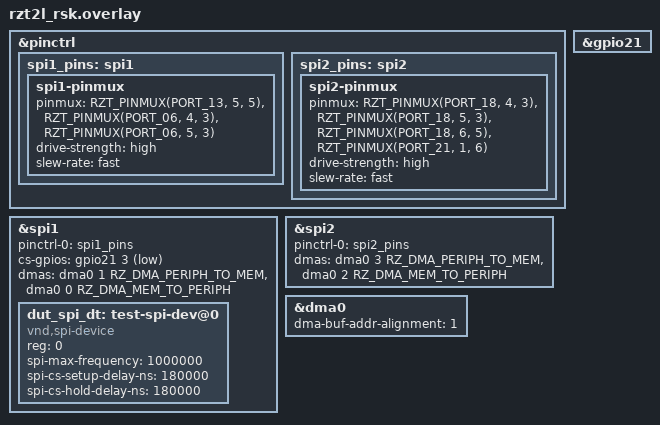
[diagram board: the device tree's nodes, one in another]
/*
 * Copyright (c) 2025 Renesas Electronics Corporation
 *
 * SPDX-License-Identifier: Apache-2.0
 */

&pinctrl {
	/omit-if-no-ref/ spi1_pins: spi1 {
		spi1-pinmux {
			pinmux = <RZT_PINMUX(PORT_13, 5, 5)>, /* CK1 */
				 <RZT_PINMUX(PORT_06, 4, 3)>, /* MOSI1 */
				 <RZT_PINMUX(PORT_06, 5, 3)>; /* MISO1 */
			drive-strength = "high";
			slew-rate = "fast";
		};
	};

	/omit-if-no-ref/ spi2_pins: spi2 {
		spi2-pinmux {
			pinmux = <RZT_PINMUX(PORT_18, 4, 3)>, /* CK2 */
				 <RZT_PINMUX(PORT_18, 5, 3)>, /* MOSI2 */
				 <RZT_PINMUX(PORT_18, 6, 5)>, /* MISO2 */
				 <RZT_PINMUX(PORT_21, 1, 6)>; /* SSL2 */
			drive-strength = "high";
			slew-rate = "fast";
		};
	};
};

&gpio21 {
	status = "okay";
};

&spi1 {
	status = "okay";
	pinctrl-0 = <&spi1_pins>;
	pinctrl-names = "default";
	cs-gpios = <&gpio21 3 GPIO_ACTIVE_LOW>;

	dmas = <&dma0 1 RZ_DMA_PERIPH_TO_MEM>,
	       <&dma0 0 RZ_DMA_MEM_TO_PERIPH>;
	dma-names = "rx", "tx";

	dut_spi_dt: test-spi-dev@0 {
		compatible = "vnd,spi-device";
		reg = <0>;
		spi-max-frequency = <1000000>;
		spi-cs-setup-delay-ns = <180000>;
		spi-cs-hold-delay-ns = <180000>;
	};
};

dut_spis: &spi2 {
	status = "okay";
	pinctrl-0 = <&spi2_pins>;
	pinctrl-names = "default";

	dmas = <&dma0 3 RZ_DMA_PERIPH_TO_MEM>,
	       <&dma0 2 RZ_DMA_MEM_TO_PERIPH>;
	dma-names = "rx", "tx";
};

&dma0 {
	status = "okay";
	dma-buf-addr-alignment = <1>;
};
